# G32R430xx register map
Vendor: Geehy Semiconductor Co., Ltd.; Series: G32R4; File version: 1.0
CPU: CM52 r0p1, little endian, MPU, no FPU, DSP, VTOR, 4 interrupt priority bits
Registers are 32-bit, read-write, reset 0x0 unless marked. A register's access mark holds for its fields unless they carry their own. Offsets are from the block's base; [hi:lo] are bit positions.

## RCM — Reset and clock manager.
Base 0x40020400
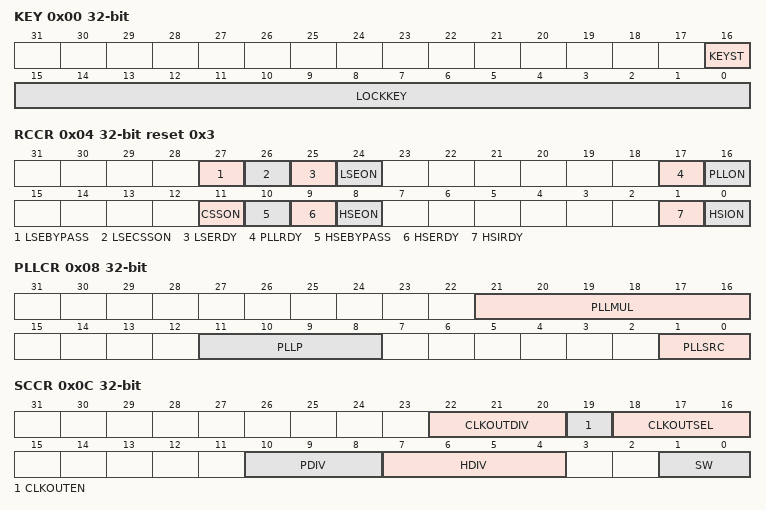
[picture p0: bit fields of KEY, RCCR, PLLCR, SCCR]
0x00 KEY access per field
  [16] KEYST rw — System Register KEY Protection Status Bit
  [15:0] LOCKKEY wo — Configuration of password protection for system register write operations
0x04 RCCR access per field reset 0x3 — Crystal Oscillator Control Register
  [27] LSEBYPASS rw — LSE BYPASS enable
  [26] LSECSSON rw — LSE clock fault detection enable
  [25] LSERDY ro — LSE READY FLAG
  [24] LSEON rw — LSE enable
  [17] PLLRDY ro — PLL READY FLAG
  [16] PLLON rw — PLL enable
  [11] CSSON rw — CSS enable
  [10] HSEBYPASS rw — HSE BYPASS enable
  [9] HSERDY ro — HSE READY FLAG
  [8] HSEON rw — HSE enable
  [1] HSIRDY ro — HSI READY FLAG
  [0] HSION rw — HSI enable
0x08 PLLCR — PLL control register
  [21:16] PLLMUL — PLL Frequency Multiplication Coefficient
  [11:8] PLLP — PLL Input Clock Division Control
  [1:0] PLLSRC — PLL Input Clock Selection
0x0C SCCR — Clock Divider Control Register
  [22:20] CLKOUTDIV — CLKOUT clock frequency output
  [19] CLKOUTEN — Clock output enable
  [18:16] CLKOUTSEL — CLKOUT clock output selection
  [10:8] PDIV — APB clock division.
  [7:4] HDIV — AHB clock division.
  [1:0] SW — System Clock Selection
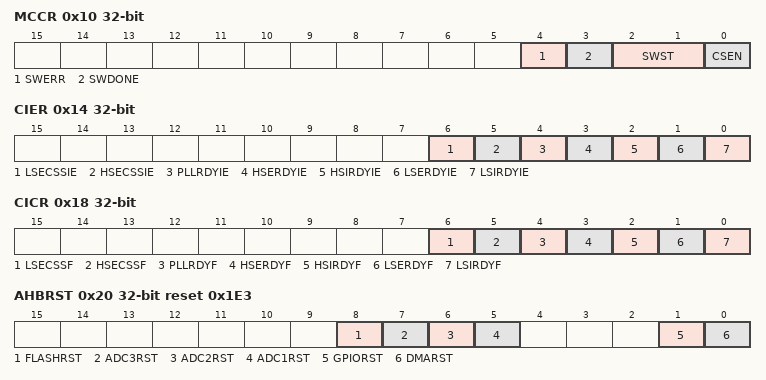
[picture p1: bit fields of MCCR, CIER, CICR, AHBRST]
0x10 MCCR access per field — Main clock control register.
  [4] SWERR ro — Toggle error flag.
  [3] SWDONE ro — Switching completion flag.
  [2:1] SWST ro — The current status of the master clock
  [0] CSEN rw — Main clock switch enable.
0x14 CIER — Timer interrupt enable register.
  [6] LSECSSIE — LSE clock fault enable
  [5] HSECSSIE — HSE clock fault enable
  [4] PLLRDYIE — PLL-ready interrupt enable
  [3] HSERDYIE — HSE-ready interrupt enable
  [2] HSIRDYIE — HSI-ready interrupt enable
  [1] LSERDYIE — LSE-ready interrupt enable
  [0] LSIRDYIE — LSI-ready interrupt enable
0x18 CICR — Interrupt flag control register
  [6] LSECSSF — LSE - Clock Fault Flag
  [5] HSECSSF — HSE - Clock Fault Flag
  [4] PLLRDYF — PLL-ready flag
  [3] HSERDYF — HSE-ready flag
  [2] HSIRDYF — HSI-ready flag
  [1] LSERDYF — LSE-ready flag
  [0] LSIRDYF — LSI-ready flag
0x20 AHBRST reset 0x1E3 — AHB Peripheral Reset Register
  [8] FLASHRST — FLASH module reset
  [7] ADC3RST — ADC3 module reset
  [6] ADC2RST — ADC2 module reset
  [5] ADC1RST — ADC1 module reset
  [1] GPIORST — GPIO module reset
  [0] DMARST — DMA module reset
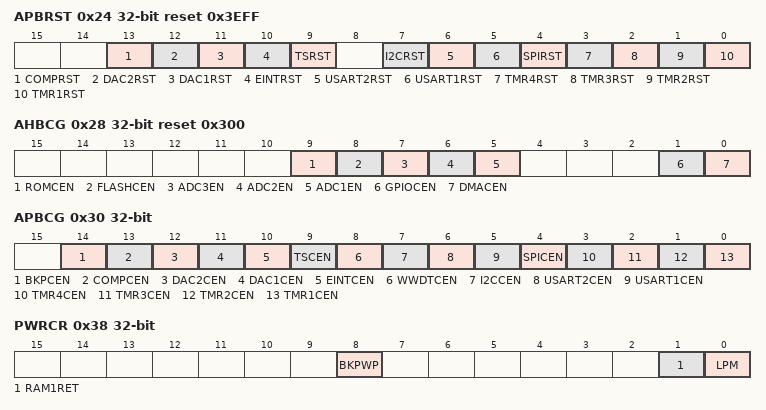
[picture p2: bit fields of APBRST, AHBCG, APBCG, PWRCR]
0x24 APBRST reset 0x3EFF — APB Peripheral Reset Register
  [13] COMPRST — COMP module reset
  [12] DAC2RST — DAC2 module reset
  [11] DAC1RST — DAC1 module reset
  [10] EINTRST — EINT module reset
  [9] TSRST — TS module reset
  [7] I2CRST — I2C module reset
  [6] USART2RST — USART2 module reset
  [5] USART1RST — USART1 module reset
  [4] SPIRST — SPI module reset
  [3] TMR4RST — TMR4 module reset
  [2] TMR3RST — TMR3 module reset
  [1] TMR2RST — TMR3 module reset
  [0] TMR1RST — TMR1 module reset
0x28 AHBCG reset 0x300 — AHB peripheral control register
  [9] ROMCEN — ROM clock enable
  [8] FLASHCEN — FLASH clock enable
  [7] ADC3EN — ADC3 clock enable
  [6] ADC2EN — ADC2 clock enable
  [5] ADC1EN — ADC1 clock enable
  [1] GPIOCEN — GPIO clock enable
  [0] DMACEN — DMA clock enable
0x30 APBCG — APB peripheral control register
  [14] BKPCEN — BKP clock enable
  [13] COMPCEN — COMP clock enable
  [12] DAC2CEN — DAC2 clock enable
  [11] DAC1CEN — DAC1 clock enable
  [10] EINTCEN — EINT clock enable
  [9] TSCEN — TS clock enable
  [8] WWDTCEN — WWDT clock enable
  [7] I2CCEN — I2C clock enable
  [6] USART2CEN — USART2 clock enable
  [5] USART1CEN — USART1 clock enable
  [4] SPICEN — SPI clock enable
  [3] TMR4CEN — TMR4 clock enable
  [2] TMR3CEN — TMR3 clock enable
  [1] TMR2CEN — TMR3 clock enable
  [0] TMR1CEN — TMR1 clock enable
0x38 PWRCR — PWR peripheral control register
  [8] BKPWP — Prohibit enabling write protection for the backup area.
  [1] RAM1RET — sram1 power failure.
  [0] LPM — Low power mode
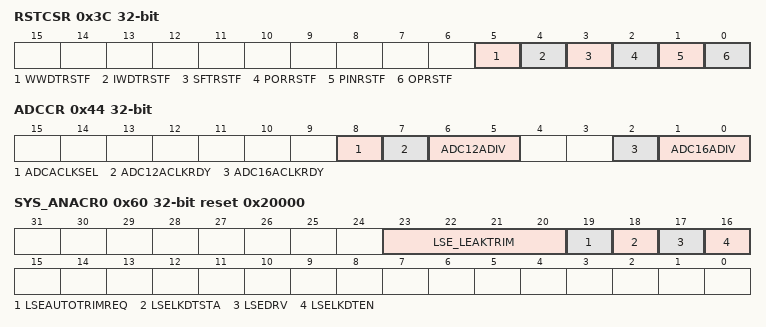
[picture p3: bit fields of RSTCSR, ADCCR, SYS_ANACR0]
0x3C RSTCSR — Clock reset status register
  [5] WWDTRSTF — Window watchdog reset.
  [4] IWDTRSTF — Reset caused by independent watchdog.
  [3] SFTRSTF — Software-induced reset
  [2] PORRSTF — Power reset caused by.
  [1] PINRSTF — Reset caused by external RST pin.
  [0] OPRSTF — Reset caused by opload.
0x44 ADCCR access per field — Analog module control register
  [8] ADCACLKSEL rw — Clock Source Selection for ADC1/2/3 ANALOG Clock Divider
  [7] ADC12ACLKRDY ro — ADC3_ANALOG Clock Status Bit
  [6:5] ADC12ADIV rw — The ADC3_ANALOG clock (with a 50% duty cycle), this value can only be changed when ADC3ACLKRDY is 0 and module ADC3 is disabled, then the value of ADC12ADIV can be altered.
  [2] ADC16ACLKRDY rw — ADC1/2_ANALOG clock status bit. When ADC1/2 is enabled, you need to wait for this BIT to be 1, then ADC can carry out the conversion.
  [1:0] ADC16ADIV rw — ADC1/2_ANALOG clock (duty ratio 75%), this value can only be changed when ADC01ACLKRDY is 0 and neither ADC1 nor ADC2 modules are enabled,to change the value of ADC16ADIV.
0x60 SYS_ANACR0 reset 0x20000 — System analog control register 0
  [23:20] LSE_LEAKTRIM — XIN port leakage compensation adjustment control
  [19] LSEAUTOTRIMREQ — LSECLK leakage compensation automatic calibration enable
  [18] LSELKDTSTA ro — Leakage detection function status
  [17] LSEDRV — LSECLK drive capacity select
  [16] LSELKDTEN — LSECLK leakage detection function enable
